# dct_to_hibi: IP-XACT component
VLNV TUT:ip.hwp.accelerator:dct_to_hibi:1.0
DCT to Hibi. Connects dctQidct block to HIBI Wrapper Input: 1. Address to send the results to quant 2. Address to send the results to idct (set unused address if you don't use this) 2. Control word for the current macroblock Control word structure: bit 6: chroma(1)/luma(0) (NOT USED), 5: intra(1)/inter(0), 4..0: quantizer parameter (QP) 3. Then the DCT data ( 8x8x6 x 16-bit values = 384 x 16 bit ) Only 9b DCT data values are supported currently. Send two DCT-values packed to upper and lower 16bits in the sigle hibi transmission. <31------------------16--------------------0> BIT index DCT_DATA_1 DCT_DATA_0 DATA NOTE: If self release is used (use_self_rel_g=1) user gets the signal that dct_to_hibi is ready to receive data. By default self release is disabled and you user can send data to dct_to_hibi after quant results are received. Outputs: Outputs are 16-bit words which are packed up to hibi. If hibi width is 32b, then 2 16-bit words are combined into one hibi word. 01. quant results: 1. 8*8 x 16bit values to quant result address 02. idct results: 1. 8*8 x 16bit values to idct result address 03. quant results: 2. 8*8 x 16bit values to quant result address 04. idct results: 2. 8*8 x 16bit values to idct result address 05. quant results: 3. 8*8 x 16bit values to quant result address 06. idct results: 3. 8*8 x 16bit values to idct result address 07. quant results: 4. 8*8 x 16bit values to quant result address 08. idct results: 4. 8*8 x 16bit values to idct result address 09. quant results: 5. 8*8 x 16bit values to quant result address 10. idct results: 5. 8*8 x 16bit values to idct result address 11. quant results: 6. 8*8 x 16bit values to quant result address 12. quant results: 1 word with bits 5..0 determing if 8x8 quant blocks(1-6) has all values zeros (except dc-component in intra) 13. idct results: 6. 8*8 x 16bit values to idct result address - Total amount of 16-bit values is: 384 per result address + 1 hibi word to quantization result address. With default parameter: Total of 193 words of data to quant address (if data_width_g = 32) Total of 192 words of data to idct address (if data_width_g = 32)

## Parameters
comm_width_g = 5
data_width_g = 32
dct_width_g = 9 — Incoming data width(9b)
debug_w_g = 1
idct_width_g = 9 — Data width after IDCT(9b)
own_address_g = 0 — Used for self-release
quant_width_g = 8 — Quantizated data width(8b)
rtm_address_g = 0 — Used for self-release
use_self_rel_g = 0 — Does it release itself from RTM?

## Bus interfaces (logical=physical port)
clk: slave TUT:ip.hwp.interface:clock.busdef:1.0 — Clock interface
  CLK[0:0]=clk[0:0]
dct_if: slave TUT:ip.hwp.accelerator:dct.busdef:1.0 — Interface for connecting idctquant accelerator
  CHROMA_TO_ACC[0:0]=chroma_out[0:0], DCT_READY4COL_FROM_ACC[0:0]=dct_ready4col_in[0:0], IDCT_READY4COL_TO_ACC[0:0]=idct_ready4col_out[0:0], INTRA_TO_ACC[0:0]=intra_out[0:0], LOAD_QP_TO_ACC[0:0]=loadQP_out[0:0], QP_TO_ACC[4:0]=QP_out[4:0], WR_DCT_TO_ACC[0:0]=wr_dct_out[0:0], WR_IDCT_FROM_ACC[0:0]=wr_idct_in[0:0], WR_QUANT_FROM_ACC[0:0]=wr_quant_in[0:0], QUANT_READY4COL_TO_ACC[0:0]=quant_ready4col_out[0:0], DATA_DCT_TO_ACC[8:0]=data_dct_out[8:0], DATA_IDCT_FROM_ACC[8:0]=data_idct_in[8:0], DATA_QUANT_FROM_ACC[7:0]=data_quant_in[7:0]
hibi_master: master TUT:ip.hwp.communication:hibi_ip_r4.busdef:3.0 — HIBI wrapper r4 version 2 master interface
  AV[0:0]=hibi_av_out[0:0], COMM[4:0]=hibi_comm_out[4:0], DATA[31:0]=hibi_data_out[31:0], RE[0:0]=hibi_re_out[0:0], WE[0:0]=hibi_we_out[0:0]
rst_n: slave TUT:ip.hwp.interface:reset.busdef:1.0 — Active low reset input.
  RESETn[0:0]=rst_n[0:0]
hibi_slave: slave TUT:ip.hwp.communication:hibi_ip_r4.busdef:3.0, memory map dct_mem_map
  AV[0:0]=hibi_av_in[0:0], COMM[4:0]=hibi_comm_in[4:0], DATA[31:0]=hibi_data_in[31:0], EMPTY[0:0]=hibi_empty_in[0:0], FULL[0:0]=hibi_full_in[0:0]

## Ports
out QP_out[4:0]
out chroma_out[0:0]
in clk
out data_dct_out[8:0]
in data_idct_in[8:0]
in data_quant_in[7:0]
in dct_ready4col_in
out debug_out[0:0]
in hibi_av_in
out hibi_av_out
in hibi_comm_in[4:0]
out hibi_comm_out[4:0]
in hibi_data_in[31:0]
out hibi_data_out[31:0]
in hibi_empty_in
in hibi_full_in
out hibi_re_out
out hibi_we_out
out idct_ready4col_out[0:0]
out intra_out
out loadQP_out
out quant_ready4col_out[0:0]
in rst_n
out wr_dct_out[0:0]
in wr_idct_in[0:0]
in wr_quant_in[0:0]

## Address spaces and blocks
dct_mem_map.dct_regs: base 0x0, range 1, width 32, register

## Registers
Registers are 32-bit, access not given, no defined reset value unless marked. A register's access mark holds for its fields unless they carry their own. Offsets are from the block's base; lines under a group give offsets from that group; [hi:lo] are bit positions; {n}, {i} and the like mark numbered series; 'fields as' and 'values as' point back to an identical list; <NAME> marks a mode.

## dct_mem_map.dct_regs
Base 0x00000000
0x00 quant_result_addr
0x01 idct_result_addr
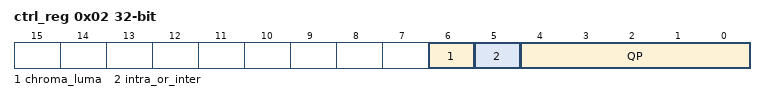
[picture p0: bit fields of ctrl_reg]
0x02 ctrl_reg
  [6] chroma_luma — 0=luma, 1=chroma
  [5] intra_or_inter — 0=intra, 1=inter
  [4:0] QP — Quant parameter
0x03 dct_data
